VERSION ""

NS_ :

BS_:

BU_:

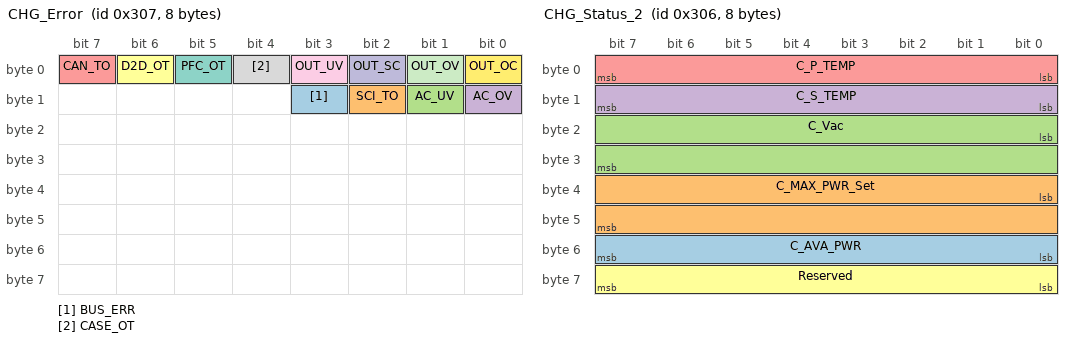
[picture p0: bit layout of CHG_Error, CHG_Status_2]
BO_ 775 CHG_Error: 8 Vector__XXX
 SG_ BUS_ERR : 11|1@1+ (1,0) [0|1] "" Vector__XXX
 SG_ SCI_TO : 10|1@1+ (1,0) [0|1] "" Vector__XXX
 SG_ AC_UV : 9|1@1+ (1,0) [0|1] "" Vector__XXX
 SG_ AC_OV : 8|1@1+ (1,0) [0|1] "" Vector__XXX
 SG_ CAN_TO : 7|1@1+ (1,0) [0|1] "" Vector__XXX
 SG_ D2D_OT : 6|1@1+ (1,0) [0|1] "" Vector__XXX
 SG_ PFC_OT : 5|1@1+ (1,0) [0|1] "" Vector__XXX
 SG_ CASE_OT : 4|1@1+ (1,0) [0|1] "" Vector__XXX
 SG_ OUT_UV : 3|1@1+ (1,0) [0|1] "" Vector__XXX
 SG_ OUT_SC : 2|1@1+ (1,0) [0|1] "" Vector__XXX
 SG_ OUT_OV : 1|1@1+ (1,0) [0|1] "" Vector__XXX
 SG_ OUT_OC : 0|1@1+ (1,0) [0|1] "" Vector__XXX

BO_ 774 CHG_Status_2: 8 Vector__XXX
 SG_ C_AVA_PWR : 48|8@1+ (1,0) [0|255] "" Vector__XXX
 SG_ C_MAX_PWR_Set : 32|16@1+ (0.1,0) [0|6553.5] "W" Vector__XXX
 SG_ C_Vac : 16|16@1+ (1,0) [0|65535] "V" Vector__XXX
 SG_ C_S_TEMP : 8|8@1- (1,0) [-128|127] "du" Vector__XXX
 SG_ C_P_TEMP : 0|8@1- (1,0) [-128|127] "du" Vector__XXX
 SG_ Reserved : 56|8@1+ (1,0) [0|255] "" Vector__XXX

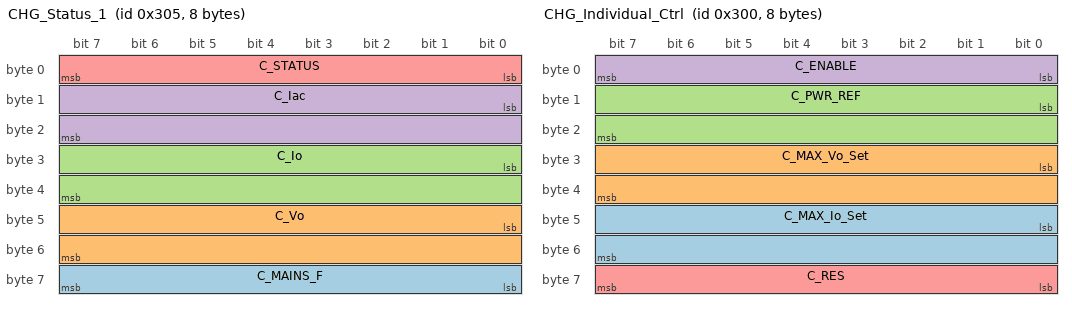
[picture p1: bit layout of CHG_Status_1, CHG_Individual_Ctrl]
BO_ 773 CHG_Status_1: 8 Vector__XXX
 SG_ C_MAINS_F : 56|8@1+ (1,0) [0|255] "Hz" Vector__XXX
 SG_ C_Vo : 40|16@1+ (0.1,0) [0|6553.5] "V" Vector__XXX
 SG_ C_Io : 24|16@1+ (0.1,0) [0|6553.5] "A" Vector__XXX
 SG_ C_Iac : 8|16@1+ (0.1,0) [0|6553.5] "A" Vector__XXX
 SG_ C_STATUS : 0|8@1+ (1,0) [0|255] "" Vector__XXX

BO_ 768 CHG_Individual_Ctrl: 8 Vector__XXX
 SG_ C_MAX_Io_Set : 40|16@1+ (0.1,0) [0|6553.5] "A" Vector__XXX
 SG_ C_MAX_Vo_Set : 24|16@1+ (0.1,0) [0|6553.5] "V" Vector__XXX
 SG_ C_PWR_REF : 8|16@1+ (0.1,0) [0|6553.5] "" Vector__XXX
 SG_ C_ENABLE : 0|8@1+ (1,0) [0|255] "" Vector__XXX
 SG_ C_RES : 56|8@1+ (1,0) [0|255] "" Vector__XXX

CM_ BO_ 775 "CHG_Error";
CM_ SG_ 775 AC_OV "Charger Low Mains shutdown (Recoverable)";
CM_ SG_ 775 CAN_TO "Charger CAN Comm.Timeout (Recoverable)";
CM_ SG_ 775 D2D_OT "Charger DC Undervolt. Shutdown (Recoverable)";
CM_ SG_ 775 PFC_OT "Charger Transformer Failure (Non Rec.)";
CM_ SG_ 775 CASE_OT "Charger Current Limit (no error)";
CM_ SG_ 775 OUT_UV "Charger Low Temp Shutdown (Recoverable)";
CM_ SG_ 775 OUT_SC "Charger High Temp Shutdown (Recoverable)";
CM_ SG_ 775 OUT_OV "Charger High Mains shutdown (Recoverable)";
CM_ SG_ 775 OUT_OC "Charger DC OverVoltage Shutdown (Recoverable)";
CM_ BO_ 774 "CHG_Status_2";
CM_ SG_ 774 C_AVA_PWR "Charger Available Power (% ofC_MAX_PWR as consequence ofTemperature and Mains Derating)";
CM_ SG_ 774 C_MAX_PWR_Set "Charger Max Power";
CM_ SG_ 774 C_Vac "Charger Mains Supply Voltage";
CM_ SG_ 774 C_S_TEMP "Charger Secondary Temp";
CM_ SG_ 774 C_P_TEMP "Charger Primary Temp";
CM_ BO_ 773 "CHG_Status_1";
CM_ SG_ 773 C_MAINS_F "Charger Mains Supply Frequency";
CM_ SG_ 773 C_Vo "Chatger DC Bus Voltage";
CM_ SG_ 773 C_Io "Charger DC Bus Current";
CM_ SG_ 773 C_Iac "Charger Mains Supply Current";
CM_ SG_ 773 C_STATUS "Charger Status";
CM_ BO_ 768 "CHG_Charger Enable";
CM_ SG_ 768 C_MAX_Io_Set "Charge Current Reference";
CM_ SG_ 768 C_MAX_Vo_Set "Charge Voltage Reference";
CM_ SG_ 768 C_PWR_REF "Charger Power Reference";
CM_ SG_ 768 C_ENABLE "Charger Enable";
BA_DEF_  "BusType" STRING ;
BA_DEF_ SG_  "GenSigStartValue" FLOAT -3.4E+038 3.4E+038;
BA_DEF_DEF_  "BusType" "CAN";
BA_DEF_DEF_  "GenSigStartValue" 0;
